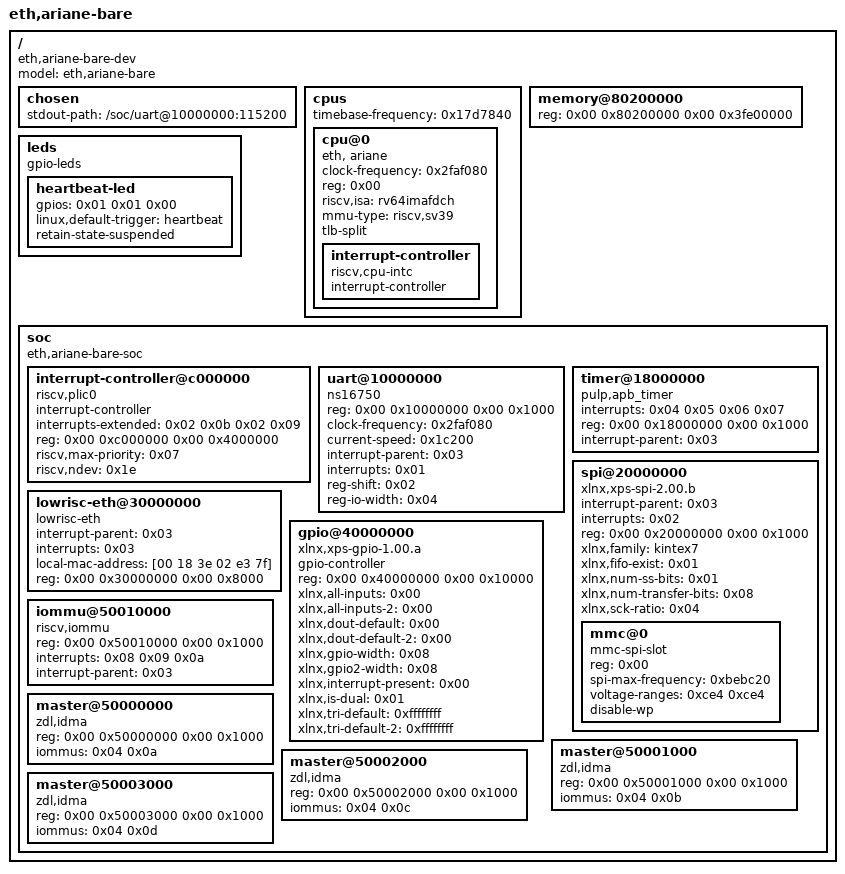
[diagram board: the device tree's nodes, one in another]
/dts-v1/;

/ {
	#address-cells = <0x02>;
	#size-cells = <0x02>;
	compatible = "eth,ariane-bare-dev";
	model = "eth,ariane-bare";

	chosen {
		stdout-path = "/soc/uart@10000000:115200";
	};

	cpus {
		#address-cells = <0x01>;
		#size-cells = <0x00>;
		timebase-frequency = <0x17d7840>;

		cpu@0 {
			clock-frequency = <0x2faf080>;
			device_type = "cpu";
			reg = <0x00>;
			status = "okay";
			compatible = "eth, ariane\0riscv";
			riscv,isa = "rv64imafdch";
			mmu-type = "riscv,sv39";
			tlb-split;

			interrupt-controller {
				#interrupt-cells = <0x01>;
				interrupt-controller;
				compatible = "riscv,cpu-intc";
				phandle = <0x02>;
			};
		};
	};

	memory@80200000 {
		device_type = "memory";
		reg = <0x00 0x80200000 0x00 0x3fe00000>;
	};

	leds {
		compatible = "gpio-leds";

		heartbeat-led {
			gpios = <0x01 0x01 0x00>;
			linux,default-trigger = "heartbeat";
			retain-state-suspended;
		};
	};

	soc {
		#address-cells = <0x02>;
		#size-cells = <0x02>;
		compatible = "eth,ariane-bare-soc\0simple-bus";
		ranges;

		interrupt-controller@c000000 {
			#address-cells = <0x00>;
			#interrupt-cells = <0x01>;
			compatible = "riscv,plic0";
			interrupt-controller;
			interrupts-extended = <0x02 0x0b 0x02 0x09>;
			reg = <0x00 0xc000000 0x00 0x4000000>;
			riscv,max-priority = <0x07>;
			riscv,ndev = <0x1e>;
			phandle = <0x03>;
		};

		uart@10000000 {
			compatible = "ns16750";
			reg = <0x00 0x10000000 0x00 0x1000>;
			clock-frequency = <0x2faf080>;
			current-speed = <0x1c200>;
			interrupt-parent = <0x03>;
			interrupts = <0x01>;
			reg-shift = <0x02>;
			reg-io-width = <0x04>;
		};

		timer@18000000 {
			compatible = "pulp,apb_timer";
			interrupts = <0x04 0x05 0x06 0x07>;
			reg = <0x00 0x18000000 0x00 0x1000>;
			interrupt-parent = <0x03>;
			reg-names = "control";
		};

		spi@20000000 {
			compatible = "xlnx,xps-spi-2.00.b\0xlnx,xps-spi-2.00.a";
			#address-cells = <0x01>;
			#size-cells = <0x00>;
			interrupt-parent = <0x03>;
			interrupts = <0x02>;
			reg = <0x00 0x20000000 0x00 0x1000>;
			xlnx,family = "kintex7";
			xlnx,fifo-exist = <0x01>;
			xlnx,num-ss-bits = <0x01>;
			xlnx,num-transfer-bits = <0x08>;
			xlnx,sck-ratio = <0x04>;

			mmc@0 {
				compatible = "mmc-spi-slot";
				reg = <0x00>;
				spi-max-frequency = <0xbebc20>;
				voltage-ranges = <0xce4 0xce4>;
				disable-wp;
			};
		};

		lowrisc-eth@30000000 {
			compatible = "lowrisc-eth";
			device_type = "network";
			interrupt-parent = <0x03>;
			interrupts = <0x03>;
			local-mac-address = [00 18 3e 02 e3 7f];
			reg = <0x00 0x30000000 0x00 0x8000>;
		};

		gpio@40000000 {
			#gpio-cells = <0x02>;
			compatible = "xlnx,xps-gpio-1.00.a";
			gpio-controller;
			reg = <0x00 0x40000000 0x00 0x10000>;
			xlnx,all-inputs = <0x00>;
			xlnx,all-inputs-2 = <0x00>;
			xlnx,dout-default = <0x00>;
			xlnx,dout-default-2 = <0x00>;
			xlnx,gpio-width = <0x08>;
			xlnx,gpio2-width = <0x08>;
			xlnx,interrupt-present = <0x00>;
			xlnx,is-dual = <0x01>;
			xlnx,tri-default = <0xffffffff>;
			xlnx,tri-default-2 = <0xffffffff>;
			phandle = <0x01>;
		};

		iommu@50010000 {
			compatible = "riscv,iommu";
			reg = <0x00 0x50010000 0x00 0x1000>;
			interrupts = <0x08 0x09 0x0a>;
			interrupt-names = "cmdq\0fltq\0hpm";
			interrupt-parent = <0x03>;
			#iommu-cells = <0x01>;
			phandle = <0x04>;
		};

		master@50000000 {
			compatible = "zdl,idma";
			reg = <0x00 0x50000000 0x00 0x1000>;
			iommus = <0x04 0x0a>;
		};

		master@50001000 {
			compatible = "zdl,idma";
			reg = <0x00 0x50001000 0x00 0x1000>;
			iommus = <0x04 0x0b>;
		};

		master@50002000 {
			compatible = "zdl,idma";
			reg = <0x00 0x50002000 0x00 0x1000>;
			iommus = <0x04 0x0c>;
		};

		master@50003000 {
			compatible = "zdl,idma";
			reg = <0x00 0x50003000 0x00 0x1000>;
			iommus = <0x04 0x0d>;
		};
	};
};
